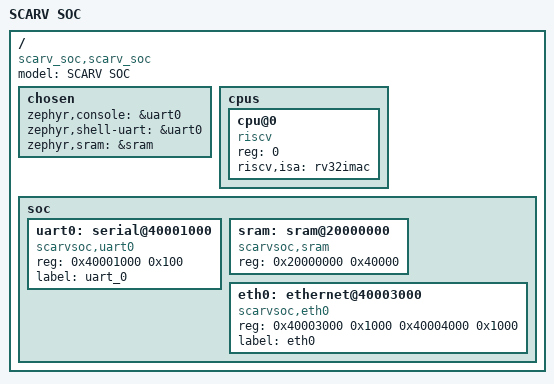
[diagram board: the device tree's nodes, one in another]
/* Copyright (c) 2019 SiFive, Inc. */
/* SPDX-License-Identifier: Apache-2.0 */

/dts-v1/;

/ {
	model = "SCARV SOC";
	compatible = "scarv_soc,scarv_soc";

	chosen {
		zephyr,console = &uart0;
		zephyr,shell-uart = &uart0;
		zephyr,sram = &sram;
		//zephyr,flash = &flash0;
	};

    cpus {
        #address-cells = <1>;
        #size-cells = <0>;
        cpu@0 {
            compatible = "riscv";
            device_type = "cpu";
            reg = <0>;
            riscv,isa = "rv32imac";
            status = "okay";
        };
    };

    soc {
        #address-cells = <1>;
        #size-cells = <1>;
        ranges;

        uart0: serial@40001000 {
            compatible = "scarvsoc,uart0";
            reg = <0x40001000 0x100>;
            reg-names = "control";
            label = "uart_0";
            status = "okay";
        };

        sram: sram@20000000 {
            compatible = "scarvsoc,sram";
            reg = <0x20000000 0x40000>;
            reg-names = "mem";
        };

        eth0: ethernet@40003000 {
            compatible = "scarvsoc,eth0";
            reg = <0x40003000 0x1000 0x40004000 0x1000>;
            reg-names = "transmit", "receive";
            label = "eth0";
        };
    };
};
